# XN11EXXX register map
File version: 1.3
CPU: CM0 r0p0, little endian, no MPU, no FPU, 2 interrupt priority bits
Registers are 32-bit, read-write, reset 0x0 unless marked. A register's access mark holds for its fields unless they carry their own. Offsets are from the block's base; [hi:lo] are bit positions; {n}, {i} and the like mark numbered series.

## SYSCON — System control register
Base 0x40048000
0x00 SYSMEMREMAP — System memory remap register
  [1:0] MAP — System memory remap
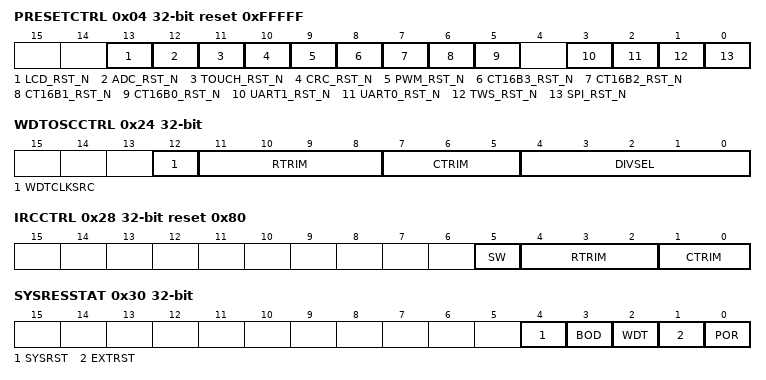
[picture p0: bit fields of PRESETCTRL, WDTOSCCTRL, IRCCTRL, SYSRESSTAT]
0x04 PRESETCTRL reset 0xFFFFF — Peripheral reset control register
  [13] LCD_RST_N — LCD control
  [12] ADC_RST_N — ADC reset control
  [11] TOUCH_RST_N — 24-bit Cap-sense timer 1 reset control
  [10] CRC_RST_N — CRC reset control
  [9] PWM_RST_N — 16-bit PWM counter/timer 1 (PWMCT) reset control
  [8] CT16B3_RST_N — 16-bit basic counter/timer 3 (CT16B3) reset control
  [7] CT16B2_RST_N — 16-bit basic counter/timer 2 (CT16B2) reset control
  [6] CT16B1_RST_N — 16-bit basic counter/timer 1 (CT16B1) reset control
  [5] CT16B0_RST_N — 16 bits basic counter/timer 0 (CT16B0) reset control
  [3] UART1_RST_N — UART1 reset control
  [2] UART0_RST_N — UART0 reset control
  [1] TWS_RST_N — TWS reset control
  [0] SPI_RST_N — SPI reset control
0x24 WDTOSCCTRL — WDT oscillator control register
  [12] WDTCLKSRC — Watch dog timer clock source
  [11:8] RTRIM — Trim watchdog oscillator resistor
  [7:5] CTRIM — Trim watchdog oscillator capacitor
  [4:0] DIVSEL — Select divider for Fclkana
0x28 IRCCTRL reset 0x80 — Internal RC oscillator control register
  [5] SW — 40MHz/48MHz switch, 0:40MHz,1:48MHz
  [4:2] RTRIM — R Trim value
  [1:0] CTRIM — C Trim value
0x30 SYSRESSTAT — System reset status register
  [4] SYSRST — Status of the software system reset
  [3] BOD — No BOD reset detected
  [2] WDT — Status of the Watchdog reset
  [1] EXTRST — Reset status
  [0] POR — POR reset status
0x70 MAINCLKSEL — Main clock source select register
  [1:0] SEL — Clock source for main clock
0x74 MAINCLKUEN — Main clock source update enable register
  [0] ENA — Enable main clock source update
0x78 SYSAHBCLKDIV reset 0x1 — System AHB clock divider register
  [7:0] DIV — System AHB clock divider value
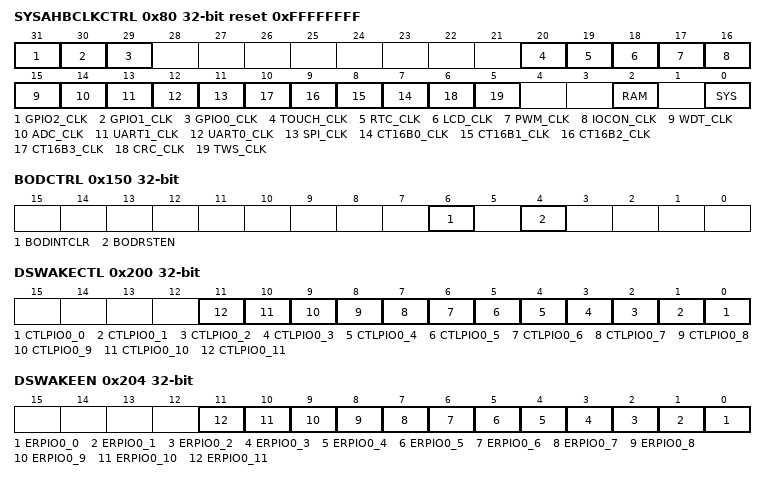
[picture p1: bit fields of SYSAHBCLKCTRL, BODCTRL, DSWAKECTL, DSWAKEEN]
0x80 SYSAHBCLKCTRL reset 0xFFFFFFFF — AHB clock control register
  [31] GPIO2_CLK — Enables clock for GPIO port 2
  [30] GPIO1_CLK — Enables clock for GPIO port 1
  [29] GPIO0_CLK — Enables clock for GPIO port 0
  [20] TOUCH_CLK — Enables clock for 24-bit Cap-sense timer
  [19] RTC_CLK — Enables clock for RTC
  [18] LCD_CLK — Enables clock for LCD CTRL
  [17] PWM_CLK — Enables clock for 16-bit PWM timer
  [16] IOCON_CLK — Enables clock for IO configuration block
  [15] WDT_CLK — Enables clock for WDT
  [14] ADC_CLK — Enables clock for ADC
  [13] UART1_CLK — Enables clock for UART1
  [12] UART0_CLK — Enables clock for UART0
  [11] SPI_CLK — Enables clock for SPI
  [n+7] CT16B{n}_CLK (n=0..3) — Enables clock for 16-bit basement counter/timer {n}
  [6] CRC_CLK — Enables clock for CRC
  [5] TWS_CLK — Enables clock for TWS
  [2] RAM — Enables clock for RAM
  [0] SYS — Enables clock for AHB to APB bridge
0x98 UART0CLKDIV — UART0 clock divider register
  [7:0] DIV — Divider value
0x9C UART1CLKDIV — UARTn Clock Divider Register
  [7:0] DIV — Divider value
0xE0 CLKOUTCLKSEL — Clockout clock source select register
  [2:0] SEL — CLKOUT clock source
0xE4 CLKOUTUEN — Clockout clock source update enable register
  [2:0] ENA — Enable CLKOUT clock source update
0xE8 CLKOUTDIV — Clockout clock divider register
  [7:0] DIV — Divider value
0x14C IOCONFIGCLKDIV — IO input filter register
  [7:0] DIV — Divider value
0x150 BODCTRL — BOD power down control register
  [6] BODINTCLR — Clear interrupt signal
  [4] BODRSTEN — BOD reset enable
0x174 INTNMI reset not defined — NMI interrupt source configuration control
  [5:0] NMISRC — NMI interrupts source select
0x200 DSWAKECTL — Deep sleep wake up control register
  [n] CTLPIO0_{n} (n=0..11) — Edge select for wake up on pin PIO0_{n} to trigger wakeup interrupt
0x204 DSWAKEEN — Deep sleep wake up signal enable control register
  [n] ERPIO0_{n} (n=0..11) — Enable pin PIO0_{n} wake up function
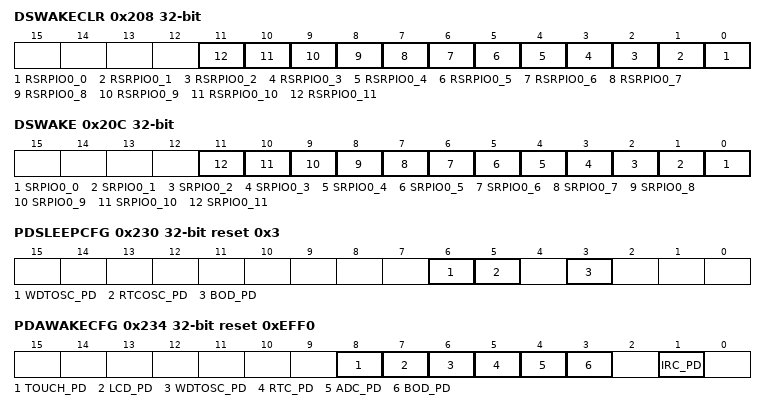
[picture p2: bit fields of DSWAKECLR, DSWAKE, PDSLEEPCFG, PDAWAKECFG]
0x208 DSWAKECLR wo — Deep sleep wake up signal reset register
  [n] RSRPIO0_{n} (n=0..11) — Wake up signal reset for pin PIO0_{n}
0x20C DSWAKE ro — Deep sleep wake up signal status register
  [n] SRPIO0_{n} (n=0..11) — Wake up signal status for PIO0_{n}
0x230 PDSLEEPCFG reset 0x3 — Power-down states in Deep-sleep mode
  [6] WDTOSC_PD — Watchdog oscillator power-down in Deep-sleep mode
  [5] RTCOSC_PD — RTC oscillator power-down control in Deep-sleep mode
  [3] BOD_PD — BOD power-down control in Deep-sleep mode
0x234 PDAWAKECFG reset 0xEFF0 — Power-down states after wake-up from Deep-sleep mode
  [8] TOUCH_PD — LCD Voltage generator power-down
  [7] LCD_PD — RTC oscillator power-down
  [6] WDTOSC_PD — Watchdog oscillator power-down
  [5] RTC_PD — RTC oscillator power-down
  [4] ADC_PD — ADC power-down
  [3] BOD_PD — BOD detector power-down
  [1] IRC_PD — IRC oscillator power-down
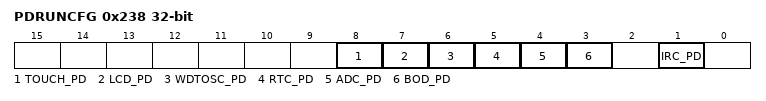
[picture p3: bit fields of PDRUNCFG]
0x238 PDRUNCFG — Power-down configuration register
  [8] TOUCH_PD — LCD Voltage generator power-down
  [7] LCD_PD — RTC oscillator power-down
  [6] WDTOSC_PD — Watchdog oscillator power-down
  [5] RTC_PD — System oscillator power-down
  [4] ADC_PD — ADC power-down
  [3] BOD_PD — BOD detector power-down
  [1] IRC_PD — IRC oscillator power-down
